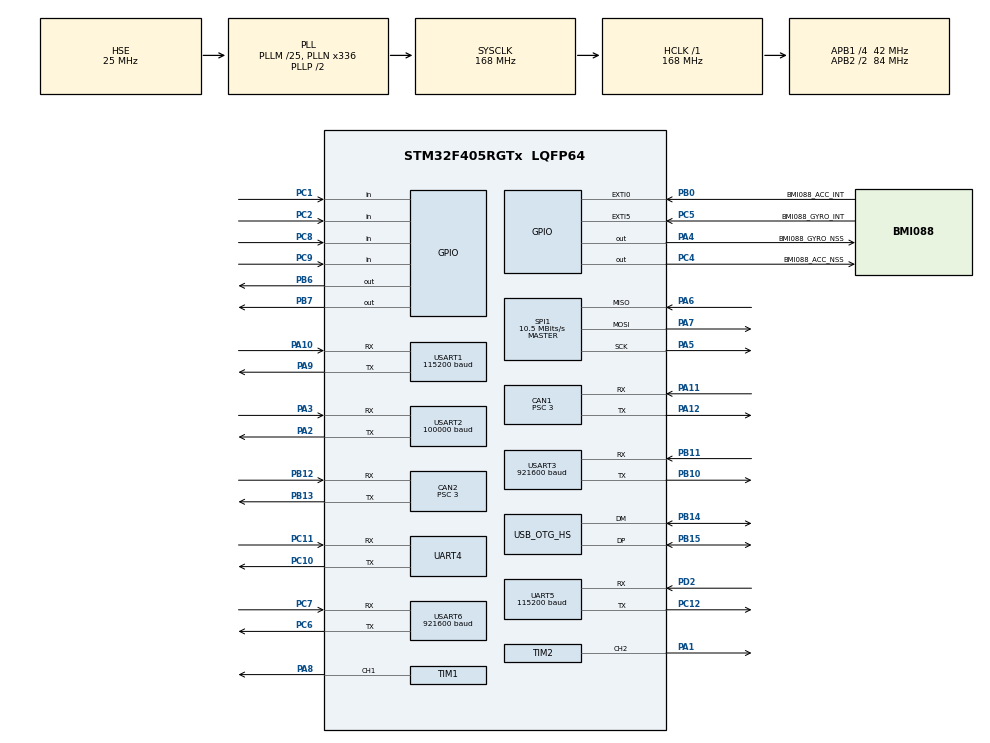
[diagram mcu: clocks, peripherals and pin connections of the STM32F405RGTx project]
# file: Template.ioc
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CAN1.ABOM=ENABLE
CAN1.BS1=CAN_BS1_9TQ
CAN1.BS2=CAN_BS2_4TQ
CAN1.CalculateBaudRate=1000000
CAN1.CalculateTimeBit=1000
CAN1.CalculateTimeQuantum=71.42857142857143
CAN1.NART=ENABLE
CAN1.Prescaler=3
CAN2.ABOM=ENABLE
CAN2.BS1=CAN_BS1_9TQ
CAN2.BS2=CAN_BS2_4TQ
CAN2.CalculateBaudRate=1000000
CAN2.CalculateTimeBit=1000
CAN2.CalculateTimeQuantum=71.42857142857143
CAN2.NART=ENABLE
CAN2.Prescaler=3
Dma.Request0=UART4_RX
Dma.Request1=UART4_TX
Dma.Request10=TIM1_CH1
Dma.Request11=UART5_TX
Dma.Request2=UART5_RX
Dma.Request3=USART1_RX
Dma.Request4=USART1_TX
Dma.Request5=USART3_RX
Dma.Request6=USART3_TX
Dma.Request7=USART6_RX
Dma.Request8=USART6_TX
Dma.Request9=USART2_RX
Dma.TIM1_CH1.10.Direction=DMA_MEMORY_TO_PERIPH
Dma.TIM1_CH1.10.FIFOMode=DMA_FIFOMODE_DISABLE
Dma.TIM1_CH1.10.Instance=DMA2_Stream3
Dma.TIM1_CH1.10.MemDataAlignment=DMA_MDATAALIGN_WORD
Dma.TIM1_CH1.10.MemInc=DMA_MINC_ENABLE
Dma.TIM1_CH1.10.Mode=DMA_NORMAL
Dma.TIM1_CH1.10.PeriphDataAlignment=DMA_PDATAALIGN_WORD
Dma.TIM1_CH1.10.PeriphInc=DMA_PINC_DISABLE
Dma.TIM1_CH1.10.Priority=DMA_PRIORITY_LOW
Dma.UART4_RX.0.Direction=DMA_PERIPH_TO_MEMORY
Dma.UART4_RX.0.FIFOMode=DMA_FIFOMODE_DISABLE
Dma.UART4_RX.0.Instance=DMA1_Stream2
Dma.UART4_RX.0.MemDataAlignment=DMA_MDATAALIGN_BYTE
Dma.UART4_RX.0.MemInc=DMA_MINC_ENABLE
Dma.UART4_RX.0.Mode=DMA_NORMAL
Dma.UART4_RX.0.PeriphDataAlignment=DMA_PDATAALIGN_BYTE
Dma.UART4_RX.0.PeriphInc=DMA_PINC_DISABLE
Dma.UART4_RX.0.Priority=DMA_PRIORITY_LOW
Dma.UART4_TX.1.Direction=DMA_MEMORY_TO_PERIPH
Dma.UART4_TX.1.FIFOMode=DMA_FIFOMODE_DISABLE
Dma.UART4_TX.1.Instance=DMA1_Stream4
Dma.UART4_TX.1.MemDataAlignment=DMA_MDATAALIGN_BYTE
Dma.UART4_TX.1.MemInc=DMA_MINC_ENABLE
Dma.UART4_TX.1.Mode=DMA_NORMAL
Dma.UART4_TX.1.PeriphDataAlignment=DMA_PDATAALIGN_BYTE
Dma.UART4_TX.1.PeriphInc=DMA_PINC_DISABLE
Dma.UART4_TX.1.Priority=DMA_PRIORITY_LOW
Dma.UART5_RX.2.Direction=DMA_PERIPH_TO_MEMORY
Dma.UART5_RX.2.FIFOMode=DMA_FIFOMODE_DISABLE
Dma.UART5_RX.2.Instance=DMA1_Stream0
Dma.UART5_RX.2.MemDataAlignment=DMA_MDATAALIGN_BYTE
Dma.UART5_RX.2.MemInc=DMA_MINC_ENABLE
Dma.UART5_RX.2.Mode=DMA_NORMAL
Dma.UART5_RX.2.PeriphDataAlignment=DMA_PDATAALIGN_BYTE
Dma.UART5_RX.2.PeriphInc=DMA_PINC_DISABLE
Dma.UART5_RX.2.Priority=DMA_PRIORITY_LOW
Dma.UART5_TX.11.Direction=DMA_MEMORY_TO_PERIPH
Dma.UART5_TX.11.FIFOMode=DMA_FIFOMODE_DISABLE
Dma.UART5_TX.11.Instance=DMA1_Stream7
Dma.UART5_TX.11.MemDataAlignment=DMA_MDATAALIGN_BYTE
Dma.UART5_TX.11.MemInc=DMA_MINC_ENABLE
Dma.UART5_TX.11.Mode=DMA_NORMAL
Dma.UART5_TX.11.PeriphDataAlignment=DMA_PDATAALIGN_BYTE
Dma.UART5_TX.11.PeriphInc=DMA_PINC_DISABLE
Dma.UART5_TX.11.Priority=DMA_PRIORITY_LOW
Dma.USART1_RX.3.Direction=DMA_PERIPH_TO_MEMORY
Dma.USART1_RX.3.FIFOMode=DMA_FIFOMODE_DISABLE
Dma.USART1_RX.3.Instance=DMA2_Stream2
Dma.USART1_RX.3.MemDataAlignment=DMA_MDATAALIGN_BYTE
Dma.USART1_RX.3.MemInc=DMA_MINC_ENABLE
Dma.USART1_RX.3.Mode=DMA_NORMAL
Dma.USART1_RX.3.PeriphDataAlignment=DMA_PDATAALIGN_BYTE
Dma.USART1_RX.3.PeriphInc=DMA_PINC_DISABLE
Dma.USART1_RX.3.Priority=DMA_PRIORITY_LOW
Dma.USART1_TX.4.Direction=DMA_MEMORY_TO_PERIPH
Dma.USART1_TX.4.FIFOMode=DMA_FIFOMODE_DISABLE
Dma.USART1_TX.4.Instance=DMA2_Stream7
Dma.USART1_TX.4.MemDataAlignment=DMA_MDATAALIGN_BYTE
Dma.USART1_TX.4.MemInc=DMA_MINC_ENABLE
Dma.USART1_TX.4.Mode=DMA_NORMAL
Dma.USART1_TX.4.PeriphDataAlignment=DMA_PDATAALIGN_BYTE
Dma.USART1_TX.4.PeriphInc=DMA_PINC_DISABLE
Dma.USART1_TX.4.Priority=DMA_PRIORITY_LOW
Dma.USART2_RX.9.Direction=DMA_PERIPH_TO_MEMORY
Dma.USART2_RX.9.FIFOMode=DMA_FIFOMODE_DISABLE
Dma.USART2_RX.9.Instance=DMA1_Stream5
Dma.USART2_RX.9.MemDataAlignment=DMA_MDATAALIGN_BYTE
Dma.USART2_RX.9.MemInc=DMA_MINC_ENABLE
Dma.USART2_RX.9.Mode=DMA_NORMAL
Dma.USART2_RX.9.PeriphDataAlignment=DMA_PDATAALIGN_BYTE
Dma.USART2_RX.9.PeriphInc=DMA_PINC_DISABLE
Dma.USART2_RX.9.Priority=DMA_PRIORITY_LOW
Dma.USART3_RX.5.Direction=DMA_PERIPH_TO_MEMORY
Dma.USART3_RX.5.FIFOMode=DMA_FIFOMODE_DISABLE
Dma.USART3_RX.5.Instance=DMA1_Stream1
Dma.USART3_RX.5.MemDataAlignment=DMA_MDATAALIGN_BYTE
Dma.USART3_RX.5.MemInc=DMA_MINC_ENABLE
Dma.USART3_RX.5.Mode=DMA_NORMAL
Dma.USART3_RX.5.PeriphDataAlignment=DMA_PDATAALIGN_BYTE
Dma.USART3_RX.5.PeriphInc=DMA_PINC_DISABLE
Dma.USART3_RX.5.Priority=DMA_PRIORITY_LOW
Dma.USART3_TX.6.Direction=DMA_MEMORY_TO_PERIPH
Dma.USART3_TX.6.FIFOMode=DMA_FIFOMODE_DISABLE
Dma.USART3_TX.6.Instance=DMA1_Stream3
Dma.USART3_TX.6.MemDataAlignment=DMA_MDATAALIGN_BYTE
Dma.USART3_TX.6.MemInc=DMA_MINC_ENABLE
Dma.USART3_TX.6.Mode=DMA_NORMAL
Dma.USART3_TX.6.PeriphDataAlignment=DMA_PDATAALIGN_BYTE
Dma.USART3_TX.6.PeriphInc=DMA_PINC_DISABLE
Dma.USART3_TX.6.Priority=DMA_PRIORITY_LOW
Dma.USART6_RX.7.Direction=DMA_PERIPH_TO_MEMORY
Dma.USART6_RX.7.FIFOMode=DMA_FIFOMODE_DISABLE
Dma.USART6_RX.7.Instance=DMA2_Stream1
Dma.USART6_RX.7.MemDataAlignment=DMA_MDATAALIGN_BYTE
Dma.USART6_RX.7.MemInc=DMA_MINC_ENABLE
Dma.USART6_RX.7.Mode=DMA_NORMAL
Dma.USART6_RX.7.PeriphDataAlignment=DMA_PDATAALIGN_BYTE
Dma.USART6_RX.7.PeriphInc=DMA_PINC_DISABLE
Dma.USART6_RX.7.Priority=DMA_PRIORITY_LOW
Dma.USART6_TX.8.Direction=DMA_MEMORY_TO_PERIPH
Dma.USART6_TX.8.FIFOMode=DMA_FIFOMODE_DISABLE
Dma.USART6_TX.8.Instance=DMA2_Stream6
Dma.USART6_TX.8.MemDataAlignment=DMA_MDATAALIGN_BYTE
Dma.USART6_TX.8.MemInc=DMA_MINC_ENABLE
Dma.USART6_TX.8.Mode=DMA_NORMAL
Dma.USART6_TX.8.PeriphDataAlignment=DMA_PDATAALIGN_BYTE
Dma.USART6_TX.8.PeriphInc=DMA_PINC_DISABLE
Dma.USART6_TX.8.Priority=DMA_PRIORITY_LOW
FREERTOS.INCLUDE_vTaskDelayUntil=1
FREERTOS.Tasks01=defaultTask,0,128,StartDefaultTask,Default,NULL
FREERTOS.configTOTAL_HEAP_SIZE=80000
FREERTOS.configUSE_COUNTING_SEMAPHORES=1
Mcu.Family=STM32F4
Mcu.Name=STM32F405RGTx
Mcu.Package=LQFP64
NVIC.CAN1_RX0_IRQn=true\:5\:0\:false\:false\:true\:true\:true\:true\:true
NVIC.CAN1_RX1_IRQn=true\:5\:0\:false\:false\:true\:true\:true\:true\:true
NVIC.CAN1_TX_IRQn=true\:5\:0\:false\:false\:true\:true\:true\:true\:true
NVIC.CAN2_RX0_IRQn=true\:5\:0\:false\:false\:true\:true\:true\:true\:true
NVIC.CAN2_RX1_IRQn=true\:5\:0\:false\:false\:true\:true\:true\:true\:true
NVIC.CAN2_TX_IRQn=true\:5\:0\:false\:false\:true\:true\:true\:true\:true
NVIC.DMA1_Stream0_IRQn=true\:5\:0\:false\:false\:true\:true\:false\:true\:true
NVIC.DMA1_Stream1_IRQn=true\:5\:0\:false\:false\:true\:true\:false\:true\:true
NVIC.DMA1_Stream2_IRQn=true\:5\:0\:false\:false\:true\:true\:false\:true\:true
NVIC.DMA1_Stream3_IRQn=true\:5\:0\:false\:false\:true\:true\:false\:true\:true
NVIC.DMA1_Stream4_IRQn=true\:5\:0\:false\:false\:true\:true\:false\:true\:true
NVIC.DMA1_Stream5_IRQn=true\:5\:0\:false\:false\:true\:true\:false\:true\:true
NVIC.DMA1_Stream7_IRQn=true\:5\:0\:false\:false\:true\:true\:false\:true\:true
NVIC.DMA2_Stream1_IRQn=true\:5\:0\:false\:false\:true\:true\:false\:true\:true
NVIC.DMA2_Stream2_IRQn=true\:5\:0\:false\:false\:true\:true\:false\:true\:true
NVIC.DMA2_Stream3_IRQn=true\:5\:0\:false\:false\:true\:true\:false\:true\:true
NVIC.DMA2_Stream6_IRQn=true\:5\:0\:false\:false\:true\:true\:false\:true\:true
NVIC.DMA2_Stream7_IRQn=true\:5\:0\:false\:false\:true\:true\:false\:true\:true
NVIC.EXTI0_IRQn=true\:5\:0\:false\:false\:true\:true\:true\:true\:false
NVIC.EXTI9_5_IRQn=true\:5\:0\:false\:false\:true\:true\:true\:true\:false
NVIC.OTG_HS_EP1_IN_IRQn=true\:5\:0\:false\:false\:true\:true\:true\:true\:true
NVIC.OTG_HS_EP1_OUT_IRQn=true\:5\:0\:false\:false\:true\:true\:true\:true\:true
NVIC.OTG_HS_IRQn=true\:5\:0\:false\:false\:true\:true\:true\:true\:true
NVIC.PriorityGroup=NVIC_PRIORITYGROUP_4
NVIC.TIM5_IRQn=true\:0\:0\:true\:false\:true\:false\:true\:true\:true
NVIC.TIM7_IRQn=true\:0\:0\:false\:false\:true\:false\:false\:true\:true
NVIC.TimeBase=TIM7_IRQn
NVIC.TimeBaseIP=TIM7
NVIC.UART4_IRQn=true\:5\:0\:false\:false\:true\:true\:true\:true\:true
NVIC.UART5_IRQn=true\:5\:0\:false\:false\:true\:true\:true\:true\:true
NVIC.USART1_IRQn=true\:5\:0\:false\:false\:true\:true\:true\:true\:true
NVIC.USART2_IRQn=true\:5\:0\:false\:false\:true\:true\:true\:true\:true
NVIC.USART3_IRQn=true\:5\:0\:false\:false\:true\:true\:true\:true\:true
NVIC.USART6_IRQn=true\:5\:0\:false\:false\:true\:true\:true\:true\:true
PA1.Signal=S_TIM2_CH2
PA10.GPIO_PuPd=GPIO_PULLUP
PA10.Mode=Asynchronous
PA10.Signal=USART1_RX
PA11.Mode=CAN_Activate
PA11.Signal=CAN1_RX
PA12.Mode=CAN_Activate
PA12.Signal=CAN1_TX
PA13.Mode=Serial_Wire
PA13.Signal=SYS_JTMS-SWDIO
PA14.Mode=Serial_Wire
PA14.Signal=SYS_JTCK-SWCLK
PA2.Mode=Asynchronous
PA2.Signal=USART2_TX
PA3.GPIO_PuPd=GPIO_PULLUP
PA3.Mode=Asynchronous
PA3.Signal=USART2_RX
PA4.GPIO_Label=BMI088_GYRO_NSS
PA4.GPIO_Speed=GPIO_SPEED_FREQ_VERY_HIGH
PA4.PinState=GPIO_PIN_SET
PA4.Signal=GPIO_Output
PA5.Mode=Full_Duplex_Master
PA5.Signal=SPI1_SCK
PA6.Mode=Full_Duplex_Master
PA6.Signal=SPI1_MISO
PA7.Mode=Full_Duplex_Master
PA7.Signal=SPI1_MOSI
PA8.Signal=S_TIM1_CH1
PA9.Mode=Asynchronous
PA9.Signal=USART1_TX
PB0.GPIO_Label=BMI088_ACC_INT
PB0.GPIO_ModeDefaultEXTI=GPIO_MODE_IT_FALLING
PB0.Signal=GPXTI0
PB10.Mode=Asynchronous
PB10.Signal=USART3_TX
PB11.GPIO_PuPd=GPIO_PULLUP
PB11.Mode=Asynchronous
PB11.Signal=USART3_RX
PB12.Mode=CAN_Activate
PB12.Signal=CAN2_RX
PB13.Mode=CAN_Activate
PB13.Signal=CAN2_TX
PB14.Mode=Device_Only_FS
PB14.Signal=USB_OTG_HS_DM
PB15.Mode=Device_Only_FS
PB15.Signal=USB_OTG_HS_DP
PB6.GPIO_ModeDefaultOutputPP=GPIO_MODE_OUTPUT_OD
PB6.GPIO_PuPd=GPIO_PULLUP
PB6.GPIO_Speed=GPIO_SPEED_FREQ_VERY_HIGH
PB6.PinState=GPIO_PIN_RESET
PB6.Signal=GPIO_Output
PB7.GPIO_ModeDefaultOutputPP=GPIO_MODE_OUTPUT_OD
PB7.GPIO_PuPd=GPIO_PULLUP
PB7.GPIO_Speed=GPIO_SPEED_FREQ_VERY_HIGH
PB7.Signal=GPIO_Output
PC1.GPIO_PuPd=GPIO_PULLUP
PC1.Signal=GPIO_Input
PC10.Mode=Asynchronous
PC10.Signal=UART4_TX
PC11.GPIO_PuPd=GPIO_PULLUP
PC11.Mode=Asynchronous
PC11.Signal=UART4_RX
PC12.Mode=Asynchronous
PC12.Signal=UART5_TX
PC2.GPIO_PuPd=GPIO_PULLUP
PC2.Signal=GPIO_Input
PC4.GPIO_Label=BMI088_ACC_NSS
PC4.GPIO_Speed=GPIO_SPEED_FREQ_VERY_HIGH
PC4.PinState=GPIO_PIN_SET
PC4.Signal=GPIO_Output
PC5.GPIO_Label=BMI088_GYRO_INT
PC5.GPIO_ModeDefaultEXTI=GPIO_MODE_IT_FALLING
PC5.Signal=GPXTI5
PC6.Mode=Asynchronous
PC6.Signal=USART6_TX
PC7.GPIO_PuPd=GPIO_PULLUP
PC7.Mode=Asynchronous
PC7.Signal=USART6_RX
PC8.GPIO_PuPd=GPIO_PULLUP
PC8.Signal=GPIO_Input
PC9.GPIO_PuPd=GPIO_PULLUP
PC9.Signal=GPIO_Input
PD2.GPIO_PuPd=GPIO_PULLUP
PD2.Mode=Asynchronous
PD2.Signal=UART5_RX
PH0-OSC_IN.Mode=HSE-External-Oscillator
PH0-OSC_IN.Signal=RCC_OSC_IN
PH1-OSC_OUT.Mode=HSE-External-Oscillator
PH1-OSC_OUT.Signal=RCC_OSC_OUT
ProjectManager.HeapSize=0x200
ProjectManager.StackSize=0x400
ProjectManager.TargetToolchain=MDK-ARM V5.27
RCC.48MHZClocksFreq_Value=48000000
RCC.AHBFreq_Value=168000000
RCC.APB1CLKDivider=RCC_HCLK_DIV4
RCC.APB1Freq_Value=42000000
RCC.APB1TimFreq_Value=84000000
RCC.APB2CLKDivider=RCC_HCLK_DIV2
RCC.APB2Freq_Value=84000000
RCC.APB2TimFreq_Value=168000000
RCC.CortexFreq_Value=168000000
RCC.HCLKFreq_Value=168000000
RCC.HSE_VALUE=25000000
RCC.HSI_VALUE=16000000
RCC.LSE_VALUE=32768
RCC.PLLM=25
RCC.PLLN=336
RCC.PLLQ=7
RCC.SYSCLKFreq_VALUE=168000000
RCC.SYSCLKSource=RCC_SYSCLKSOURCE_PLLCLK
RCC.VCOOutputFreq_Value=336000000
SH.S_TIM1_CH1.0=TIM1_CH1,PWM Generation1 CH1
SH.S_TIM2_CH2.0=TIM2_CH2,PWM Generation2 CH2
SPI1.BaudRatePrescaler=SPI_BAUDRATEPRESCALER_8
SPI1.CalculateBaudRate=10.5 MBits/s
SPI1.Direction=SPI_DIRECTION_2LINES
SPI1.Mode=SPI_MODE_MASTER
SPI1.VirtualType=VM_MASTER
TIM1.Channel-PWM\ Generation1\ CH1=TIM_CHANNEL_1
TIM1.Period=104
TIM1.Prescaler=0
TIM2.Channel-PWM\ Generation2\ CH2=TIM_CHANNEL_2
TIM2.Period=19999
TIM2.Prescaler=83
TIM5.Prescaler=84-1
UART4.VirtualMode=Asynchronous
UART5.BaudRate=115200
UART5.VirtualMode=Asynchronous
USART1.BaudRate=115200
USART1.VirtualMode=VM_ASYNC
USART2.BaudRate=100000
USART2.Mode=MODE_RX
USART2.Parity=PARITY_EVEN
USART2.VirtualMode=VM_ASYNC
USART2.WordLength=WORDLENGTH_9B
USART3.BaudRate=921600
USART3.VirtualMode=VM_ASYNC
USART6.BaudRate=921600
USART6.VirtualMode=VM_ASYNC
USB_DEVICE.APP_RX_DATA_SIZE-CDC_HS=512
USB_DEVICE.APP_TX_DATA_SIZE-CDC_HS=512
USB_DEVICE.CLASS_NAME_HS=CDC
USB_DEVICE.VirtualMode-CDC_HS=Cdc
USB_DEVICE.VirtualModeHS=Cdc_HS
USB_OTG_HS.VirtualMode-Device_Only_FS=Device_Only_FS
VP_FREERTOS_VS_CMSIS_V1.Mode=CMSIS_V1
VP_SYS_VS_tim7.Mode=TIM7
VP_TIM1_VS_ClockSourceINT.Mode=Internal
VP_TIM2_VS_ClockSourceINT.Mode=Internal
VP_TIM5_VS_ClockSourceINT.Mode=Internal
VP_USB_DEVICE_VS_USB_DEVICE_CDC_HS.Mode=CDC_HS
board=custom

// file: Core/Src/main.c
/* USER CODE BEGIN Header */
/**
  ******************************************************************************
  * @file           : main.c
  * @brief          : Main program body
  ******************************************************************************
  * @attention
  *
  * <h2><center>&copy; Copyright (c) 2019 STMicroelectronics.
  * All rights reserved.</center></h2>
  *
  * This software component is licensed by ST under Ultimate Liberty license
  * SLA0044, the "License"; You may not use this file except in compliance with
  * the License. You may obtain a copy of the License at:
  *                             www.st.com/SLA0044
  *
  ******************************************************************************
  */
/* USER CODE END Header */
#include "main.h"
#include "cmsis_os.h"
#include "can.h"
#include "dma.h"
#include "spi.h"
#include "tim.h"
#include "usart.h"
#include "usb_device.h"
#include "gpio.h"

/* USER CODE BEGIN Includes */
#include "SEGGER_SYSVIEW.h"
#include "app.h"
/* USER CODE END Includes */

void SystemClock_Config(void);
void MX_FREERTOS_Init(void);

int main(void)
{

  /* MCU Configuration--------------------------------------------------------*/

  /* Reset of all peripherals, Initializes the Flash interface and the Systick. */
  HAL_Init();

  /* Configure the system clock */
  SystemClock_Config();

  /* Initialize all configured peripherals */
  MX_GPIO_Init();
  MX_DMA_Init();
  MX_CAN1_Init();
  MX_CAN2_Init();
  MX_UART4_Init();
  MX_UART5_Init();
  MX_USART1_UART_Init();
  MX_USART2_UART_Init();
  MX_USART3_UART_Init();
  MX_USART6_UART_Init();
  MX_SPI1_Init();
  MX_TIM5_Init();
  MX_TIM1_Init();
  MX_TIM2_Init();
  /* USER CODE BEGIN 2 */
  //如果SRML定时器的中断受到FreeRTOS管辖，System_Device_Init()要在FreeRTOS内核�???始运行后才能使用
  //如果在RTOS内核�???始之前运行，会与drv_time的USE_MODULE_DELAY冲突，因为如果TIM中断归RTOS管辖，因此RTOS内核�???启之前TIM中断不会�???�???
  //SEGGER_SYSVIEW_Conf()要放在RTOS内核�???始之前才能正常使�???
  System_Device_Init();
  SEGGER_SYSVIEW_Conf();
  /* USER CODE END 2 */

  /* Call init function for freertos objects (in freertos.c) */
  MX_FREERTOS_Init();

  /* Start scheduler */
  osKernelStart();
  /* We should never get here as control is now taken by the scheduler */
  /* Infinite loop */
  while (1)
  {

  }
}

void SystemClock_Config(void)
{
  RCC_OscInitTypeDef RCC_OscInitStruct = {0};
  RCC_ClkInitTypeDef RCC_ClkInitStruct = {0};

  /** Configure the main internal regulator output voltage
  */
  __HAL_RCC_PWR_CLK_ENABLE();
  __HAL_PWR_VOLTAGESCALING_CONFIG(PWR_REGULATOR_VOLTAGE_SCALE1);

  /** Initializes the RCC Oscillators according to the specified parameters
  * in the RCC_OscInitTypeDef structure.
  */
  RCC_OscInitStruct.OscillatorType = RCC_OSCILLATORTYPE_HSE;
  RCC_OscInitStruct.HSEState = RCC_HSE_ON;
  RCC_OscInitStruct.PLL.PLLState = RCC_PLL_ON;
  RCC_OscInitStruct.PLL.PLLSource = RCC_PLLSOURCE_HSE;
  RCC_OscInitStruct.PLL.PLLM = 25;
  RCC_OscInitStruct.PLL.PLLN = 336;
  RCC_OscInitStruct.PLL.PLLP = RCC_PLLP_DIV2;
  RCC_OscInitStruct.PLL.PLLQ = 7;
  if (HAL_RCC_OscConfig(&RCC_OscInitStruct) != HAL_OK)
  {
    Error_Handler();
  }

  /** Initializes the CPU, AHB and APB buses clocks
  */
  RCC_ClkInitStruct.ClockType = RCC_CLOCKTYPE_HCLK|RCC_CLOCKTYPE_SYSCLK
                              |RCC_CLOCKTYPE_PCLK1|RCC_CLOCKTYPE_PCLK2;
  RCC_ClkInitStruct.SYSCLKSource = RCC_SYSCLKSOURCE_PLLCLK;
  RCC_ClkInitStruct.AHBCLKDivider = RCC_SYSCLK_DIV1;
  RCC_ClkInitStruct.APB1CLKDivider = RCC_HCLK_DIV4;
  RCC_ClkInitStruct.APB2CLKDivider = RCC_HCLK_DIV2;

  if (HAL_RCC_ClockConfig(&RCC_ClkInitStruct, FLASH_LATENCY_5) != HAL_OK)
  {
    Error_Handler();
  }
}

void HAL_TIM_PeriodElapsedCallback(TIM_HandleTypeDef *htim)
{
  if (htim->Instance == TIM7) {
    HAL_IncTick();
  }
}

void Error_Handler(void)
{
}

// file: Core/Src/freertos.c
/* USER CODE BEGIN Header */
/**
  ******************************************************************************
  * File Name          : freertos.c
  * Description        : Code for freertos applications
  ******************************************************************************
  * @attention
  *
  * <h2><center>&copy; Copyright (c) 2019 STMicroelectronics.
  * All rights reserved.</center></h2>
  *
  * This software component is licensed by ST under Ultimate Liberty license
  * SLA0044, the "License"; You may not use this file except in compliance with
  * the License. You may obtain a copy of the License at:
  *                             www.st.com/SLA0044
  *
  ******************************************************************************
  */
/* USER CODE END Header */

#include "FreeRTOS.h"
#include "task.h"
#include "main.h"
#include "cmsis_os.h"

/* USER CODE BEGIN Includes */
#include "app.h"
/* USER CODE END Includes */

osThreadId defaultTaskHandle;

void StartDefaultTask(void const * argument);

extern void MX_USB_DEVICE_Init(void);
void MX_FREERTOS_Init(void); /* (MISRA C 2004 rule 8.1) */

/* GetIdleTaskMemory prototype (linked to static allocation support) */
void vApplicationGetIdleTaskMemory( StaticTask_t **ppxIdleTaskTCBBuffer, StackType_t **ppxIdleTaskStackBuffer, uint32_t *pulIdleTaskStackSize );

/* USER CODE BEGIN GET_IDLE_TASK_MEMORY */
static StaticTask_t xIdleTaskTCBBuffer;
static StackType_t xIdleStack[configMINIMAL_STACK_SIZE];

void vApplicationGetIdleTaskMemory( StaticTask_t **ppxIdleTaskTCBBuffer, StackType_t **ppxIdleTaskStackBuffer, uint32_t *pulIdleTaskStackSize )
{
  *ppxIdleTaskTCBBuffer = &xIdleTaskTCBBuffer;
  *ppxIdleTaskStackBuffer = &xIdleStack[0];
  *pulIdleTaskStackSize = configMINIMAL_STACK_SIZE;
  /* place for user code */
}
/* USER CODE END GET_IDLE_TASK_MEMORY */

void MX_FREERTOS_Init(void) {

  /* Create the thread(s) */
  /* definition and creation of defaultTask */
  osThreadDef(defaultTask, StartDefaultTask, osPriorityNormal, 0, 128);
  defaultTaskHandle = osThreadCreate(osThread(defaultTask), NULL);

}

void StartDefaultTask(void const * argument)
{
  /* init code for USB_DEVICE */
  MX_USB_DEVICE_Init();
  /* USER CODE BEGIN StartDefaultTask */
  // System_Device_Init();
  System_Task_Init();
  vTaskDelete(NULL);
  /* Infinite loop */
  for(;;)
  {
    osDelay(1);
  }
  /* USER CODE END StartDefaultTask */
}
